# RA4M1 register map
Vendor: Renesas Electronics Corporation; Series: RA4; File version: 1.2
CPU: CM4 r0p1, little endian, MPU, FPU, VTOR, 4 interrupt priority bits
Registers are 8-bit, read-write, reset 0x0 unless marked. A register's access mark holds for its fields unless they carry their own. Offsets are from the block's base; [hi:lo] are bit positions; 'fields as' and 'values as' point back to an identical list.

## DMAC0 — Direct memory access controller 0
Base 0x40005000
Same registers: DMAC1 0x40005040, DMAC2 0x40005080, DMAC3 0x400050C0
0x00 DMSAR 32-bit — DMA Source Address Register
  [31:0] DMSAR — Specifies the transfer source start address.
0x04 DMDAR 32-bit — DMA Destination Address Register
  [31:0] DMDAR — Specifies the transfer destination start address.
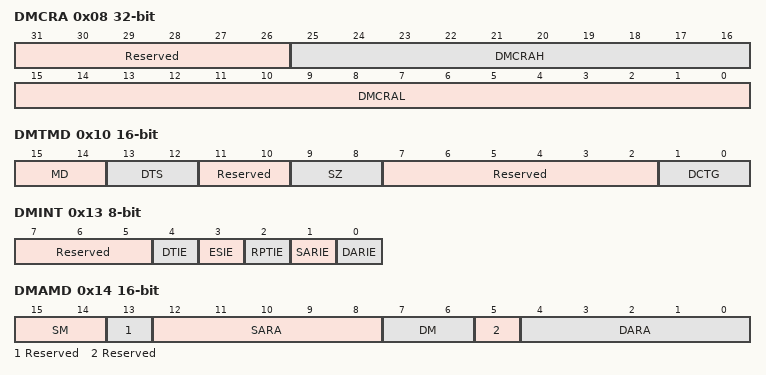
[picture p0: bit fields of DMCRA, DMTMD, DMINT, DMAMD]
0x08 DMCRA 32-bit — DMA Transfer Count Register
  [31:26] Reserved — These bits are read as 000000. The write value should be 000000.
  [25:16] DMCRAH — Upper bits of transfer count
  [15:0] DMCRAL — Lower bits of transfer count
0x0C DMCRB 16-bit — DMA Block Transfer Count Register
  [15:0] DMCRB — Specifies the number of block transfer operations or repeat transfer operations.
    0=65,536 blocks; other=others (DMCRB blocks)
0x10 DMTMD 16-bit — DMA Transfer Mode Register
  [15:14] MD — Transfer Mode Select
    0=Normal transfer; 1=Repeat transfer; 2=Block transfer; 3=Setting prohibited
  [13:12] DTS — Repeat Area Select
    0=The destination is specified as the repeat area or block area; 1=The source is specified as the repeat area or block area; 2=The repeat area or block area is not specified; 3=Setting prohibited
  [11:10] Reserved — These bits are read as 00. The write value should be 00.
  [9:8] SZ — Transfer Data Size Select
    0=8 bits; 1=16 bits; 2=32 bits; 3=Setting prohibited
  [7:2] Reserved — These bits are read as 000000. The write value should be 000000.
  [1:0] DCTG — Transfer Request Source Select
    0=Software; 1=Interrupts*1 from peripheral modules or external interrupt input pins; 2=Setting prohibited; 3=Setting prohibited
0x13 DMINT — DMA Interrupt Setting Register
  [7:5] Reserved — These bits are read as 000. The write value should be 000.
  [4] DTIE — Transfer End Interrupt Enable
    0=Disabled; 1=Enabled
  [3] ESIE — Transfer Escape End Interrupt Enable
    0=Disabled; 1=Enabled
  [2] RPTIE — Repeat Size End Interrupt Enable
    0=Disabled; 1=Enabled
  [1] SARIE — Source Address Extended Repeat Area Overflow Interrupt Enable
    0=Disabled; 1=Enabled
  [0] DARIE — Destination Address Extended Repeat Area Overflow Interrupt Enable
    0=Disabled; 1=Enabled
0x14 DMAMD 16-bit — DMA Address Mode Register
  [15:14] SM — Source Address Update Mode
    0=Fixed address; 1=Offset addition; 2=Incremented address; 3=Decremented address
  [13] Reserved — This bit is read as 0. The write value should be 0.
  [12:8] SARA — Source Address Extended Repeat Area Specifies the extended repeat area on the source address. For details on the settings.
  [7:6] DM — Destination Address Update Mode
    values as SM
  [5] Reserved — This bit is read as 0. The write value should be 0.
  [4:0] DARA — Destination Address Extended Repeat Area Specifies the extended repeat area on the destination address. For details on the settings.
0x18 DMOFR 32-bit — DMA Offset Register
  [31:0] DMOFR — Specifies the offset when offset addition is selected as the address update mode for transfer source or destination.
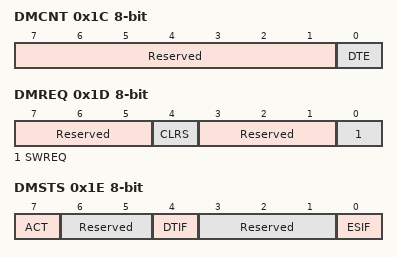
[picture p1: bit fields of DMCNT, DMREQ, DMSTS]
0x1C DMCNT — DMA Transfer Enable Register
  [7:1] Reserved — These bits are read as 0000000. The write value should be 0000000.
  [0] DTE read-modifies — DMA Transfer Enable
    0=Disabled; 1=Enabled
0x1D DMREQ — DMA Software Start Register
  [7:5] Reserved — These bits are read as 000. The write value should be 000.
  [4] CLRS — DMA Software Start Bit Auto Clear Select
    0=SWREQ bit is cleared after DMA transfer is started by software; 1=SWREQ bit is not cleared after DMA transfer is started by software
  [3:1] Reserved — These bits are read as 000. The write value should be 000.
  [0] SWREQ read-modifies — DMA Software Start
    0=DMA transfer is not requested; 1=DMA transfer is requested
0x1E DMSTS — DMA Status Register
  [7] ACT ro — DMA Active Flag
    0=DMAC operation suspended; 1=DMAC operating
  [6:5] Reserved — These bits are read as 00. The write value should be 00.
  [4] DTIF write-0-clears read-modifies — Transfer End Interrupt Flag
    0=No interrupt; 1=Interrupt occurred
  [3:1] Reserved — These bits are read as 000. The write value should be 000.
  [0] ESIF write-0-clears read-modifies — Transfer Escape End Interrupt Flag
    0=No interrupt; 1=Interrupt occurred
